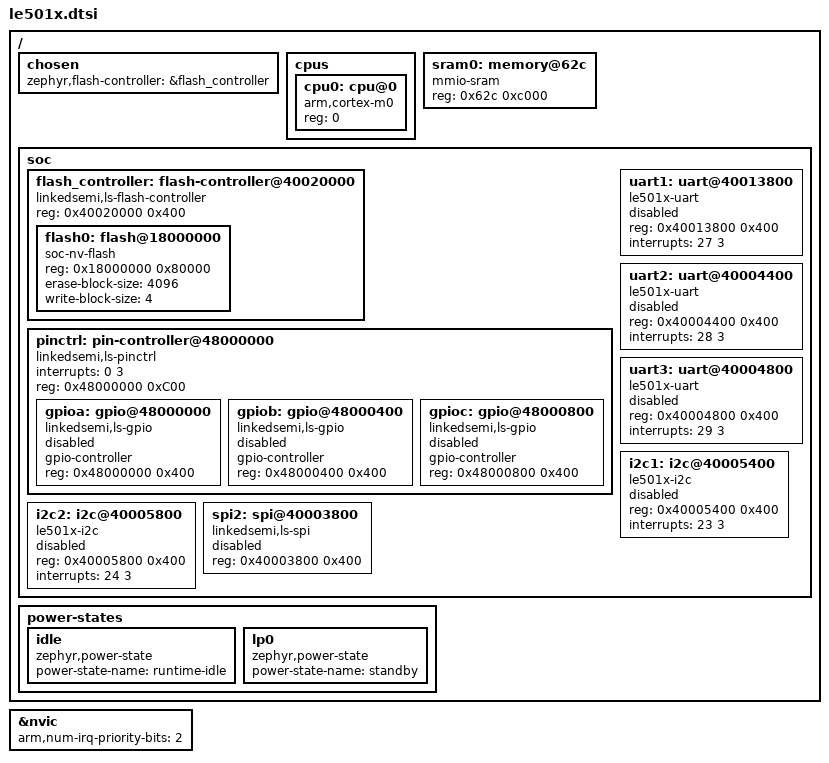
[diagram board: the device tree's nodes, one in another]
#include <arm/armv6-m.dtsi>
#include <zephyr/dt-bindings/gpio/gpio.h>

/ {
    chosen {
		zephyr,flash-controller = &flash_controller;
	};

    cpus {
		#address-cells = <1>;
		#size-cells = <0>;

		cpu0: cpu@0 {
			device_type = "cpu";
			compatible = "arm,cortex-m0";
			reg = <0>;
		};
    };

    sram0: memory@62c {
        compatible = "mmio-sram";
        reg = <0x62c 0xc000>;
    };

    soc {

        flash_controller: flash-controller@40020000 {
            compatible = "linkedsemi,ls-flash-controller";
            reg = <0x40020000 0x400>;
            #address-cells = <1>;
            #size-cells = <1>;

            flash0: flash@18000000 {
                compatible = "soc-nv-flash";
                reg = <0x18000000 0x80000>;
                erase-block-size = <4096>;
                write-block-size = <4>;
            };
        };

        pinctrl: pin-controller@48000000 {
			compatible = "linkedsemi,ls-pinctrl";
			interrupts = <0 3>;
			interrupt-names = "EXTI_GPIO";
            reg = <0x48000000 0xC00>;
			#address-cells = <1>;
			#size-cells = <1>;
            
			gpioa: gpio@48000000 {
				compatible = "linkedsemi,ls-gpio";
				gpio-controller;
				#gpio-cells = <2>;
				reg = <0x48000000 0x400>;
                status = "disabled";
			};

			gpiob: gpio@48000400 {
				compatible = "linkedsemi,ls-gpio";
				gpio-controller;
				#gpio-cells = <2>;
				reg = <0x48000400 0x400>;
                status = "disabled";
			};

			gpioc: gpio@48000800 {
				compatible = "linkedsemi,ls-gpio";
				gpio-controller;
				#gpio-cells = <2>;
				reg = <0x48000800 0x400>;
                status = "disabled";
			};
        };

        uart1: uart@40013800 {
            compatible = "le501x-uart";
            reg = <0x40013800 0x400>;
			status = "disabled";
            // label = "UART1";
            interrupts = <27 3> ;
        };

        uart2: uart@40004400 {
            compatible = "le501x-uart";
            reg = <0x40004400 0x400>;
			status = "disabled";
            // label = "UART2";
            interrupts = <28 3> ;
        };

        uart3: uart@40004800 {
            compatible = "le501x-uart";
            reg = <0x40004800 0x400>;
			status = "disabled";
            // label = "UART3";
            interrupts = <29 3> ;
        };
        i2c1: i2c@40005400 {
            compatible = "le501x-i2c";
            #address-cells = <1>;
            #size-cells = <0>;
            reg = <0x40005400 0x400>;
            interrupts = <23 3>;
            interrupt-names = "i2c1";
            status = "disabled";
        };

        i2c2: i2c@40005800 {
            compatible = "le501x-i2c";
            #address-cells = <1>;
            #size-cells = <0>;
            reg = <0x40005800 0x400>;
            interrupts = <24 3>;
            interrupt-names = "i2c2";
            status = "disabled";
        };

        spi2: spi@40003800 {
			compatible = "linkedsemi,ls-spi";
			#address-cells = <1>;
			#size-cells = <0>;
			reg = <0x40003800 0x400>;
            // interrupts = <26 0>;
			status = "disabled";
		};
    };

    power-states {
        idle: idle{
            compatible = "zephyr,power-state";
			power-state-name = "runtime-idle";
        };
        
        lp0: lp0 {
			compatible = "zephyr,power-state";
			power-state-name = "standby";
        };
    };
};

&nvic {
	arm,num-irq-priority-bits = <2>;
};
